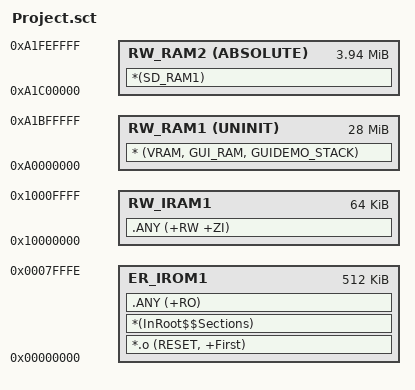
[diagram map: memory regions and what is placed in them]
; *************************************************************
; *** Scatter-Loading Description File generated by uVision ***
; *************************************************************

LR_IROM1 0x00000000 0x0007FFFF  {    ; load region size_region
  ER_IROM1 0x00000000 0x0007FFFF  {  ; load address = execution address
   *.o (RESET, +First)
   *(InRoot$$Sections)
   .ANY (+RO)
  }
  RW_IRAM1 0x10000000 0x00010000  {  ; RW data
   .ANY (+RW +ZI)
  }
  RW_RAM1 0xA0000000 UNINIT 0x01C00000  {  ; RW data
   * (VRAM, GUI_RAM, GUIDEMO_STACK)
  }
   RW_RAM2 0xA1C00000 ABSOLUTE 0x003F0000  {  ; RW data
   *(SD_RAM1);.ANY (SD_RAM1)
  }
;  RW_RAM3 0xA1FF0000 ABSOLUTE 0x10000{;RW data
;   *(SD_RAM2);.ANY (SD_RAM2)
;   }
}


